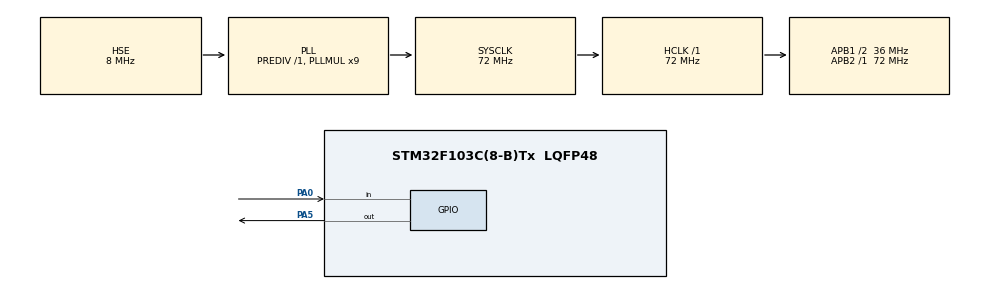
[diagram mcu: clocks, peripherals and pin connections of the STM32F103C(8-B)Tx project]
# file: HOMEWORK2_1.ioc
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Mcu.Family=STM32F1
Mcu.Name=STM32F103C(8-B)Tx
Mcu.Package=LQFP48
NVIC.PriorityGroup=NVIC_PRIORITYGROUP_4
NVIC.TIM3_IRQn=true\:0\:0\:false\:false\:true\:true\:true\:true
PA0-WKUP.GPIO_PuPd=GPIO_PULLUP
PA0-WKUP.Signal=GPIO_Input
PA13.Mode=Serial_Wire
PA13.Signal=SYS_JTMS-SWDIO
PA14.Mode=Serial_Wire
PA14.Signal=SYS_JTCK-SWCLK
PA5.Signal=GPIO_Output
PD0-OSC_IN.Mode=HSE-External-Oscillator
PD0-OSC_IN.Signal=RCC_OSC_IN
PD1-OSC_OUT.Mode=HSE-External-Oscillator
PD1-OSC_OUT.Signal=RCC_OSC_OUT
ProjectManager.HeapSize=0x200
ProjectManager.StackSize=0x400
ProjectManager.TargetToolchain=MDK-ARM V5.32
RCC.AHBFreq_Value=72000000
RCC.APB1CLKDivider=RCC_HCLK_DIV2
RCC.APB1Freq_Value=36000000
RCC.APB1TimFreq_Value=72000000
RCC.APB2Freq_Value=72000000
RCC.APB2TimFreq_Value=72000000
RCC.HCLKFreq_Value=72000000
RCC.PLLMUL=RCC_PLL_MUL9
RCC.PLLSourceVirtual=RCC_PLLSOURCE_HSE
RCC.SYSCLKFreq_VALUE=72000000
RCC.SYSCLKSource=RCC_SYSCLKSOURCE_PLLCLK
RCC.USBFreq_Value=72000000
TIM3.Period=999
TIM3.Prescaler=72
VP_TIM3_VS_ClockSourceINT.Mode=Internal
board=custom

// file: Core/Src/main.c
/* USER CODE BEGIN Header */
/**
  ******************************************************************************
  * @file           : main.c
  * @brief          : Main program body
  ******************************************************************************
  * @attention
  *
  * Copyright (c) 2026 STMicroelectronics.
  * All rights reserved.
  *
  * This software is licensed under terms that can be found in the LICENSE file
  * in the root directory of this software component.
  * If no LICENSE file comes with this software, it is provided AS-IS.
  *
  ******************************************************************************
  */
/* USER CODE END Header */
#include "main.h"

TIM_HandleTypeDef htim3;

void SystemClock_Config(void);
static void MX_GPIO_Init(void);
static void MX_TIM3_Init(void);

/* USER CODE BEGIN 0 */
volatile uint32_t lunxun1ms =0;//1ms轮询计数
volatile uint32_t led_est =0;//老灯的状态
volatile uint32_t butten_est =0;//按键的状态
volatile uint32_t butten_time =0;//按键按下的时间
volatile uint32_t led_flash_time =0;//快闪时间
/* USER CODE END 0 */

int main(void)
{

  /* MCU Configuration--------------------------------------------------------*/

  /* Reset of all peripherals, Initializes the Flash interface and the Systick. */
  HAL_Init();

  /* Configure the system clock */
  SystemClock_Config();

  /* Initialize all configured peripherals */
  MX_GPIO_Init();
  MX_TIM3_Init();
  /* USER CODE BEGIN 2 */
HAL_TIM_Base_Start_IT(&htim3);//启动定时器3中断
  /* USER CODE END 2 */

  /* Infinite loop */
  while (1)
  {

    /* USER CODE BEGIN 3 */
    if (butten_est == 0)//按键不动
    {
      if (HAL_GPIO_ReadPin(GPIOA, GPIO_PIN_0) == GPIO_PIN_RESET)//按键按下
      {
        butten_est = 1;//按键状态为按下
        butten_time = lunxun1ms;//记录按键按下的时间
      }
    }
    else if (butten_est == 1)//按键按下
    {
      if (HAL_GPIO_ReadPin(GPIOA, GPIO_PIN_0) == GPIO_PIN_SET)//按键松开
      {

        butten_time = lunxun1ms - butten_time;//计算按键按下的时间
        if (butten_time >= 20)
        {
          if(butten_time < 1000)//按键按下时间小于1秒
          {
            if(led_est ==1)
            led_est =0;//老灯熄灭
            else
            led_est =1;//老灯一直亮
          }
          else if(butten_time >= 1000)//按键按下时间大于等于1秒
          {
            if(led_est ==2)
            {
              led_est =0;//老灯熄灭
            }
            else
            {
              led_est =2;//老灯快闪
              led_flash_time = lunxun1ms;//记录快闪开始的时间
            }
          }
        }
        butten_est = 0;//按钮归零
      }
    }
    //灯光明天做上面的代码别改(；′⌒`)累死了
    if (led_est == 0)//老灯熄灭
    {
      HAL_GPIO_WritePin(GPIOA, GPIO_PIN_5, GPIO_PIN_RESET);//PA5引脚输出低电平
    }
    else if (led_est == 1)//老灯一直亮
    {
      HAL_GPIO_WritePin(GPIOA, GPIO_PIN_5, GPIO_PIN_SET);//PA5引脚输出高电平
    }
    else if (led_est == 2)//老灯快闪
    {
      if (lunxun1ms - led_flash_time >= 100)//快闪时间为100ms
      {
        HAL_GPIO_TogglePin(GPIOA, GPIO_PIN_5);//将大灯逆转吧hhhhhh
        led_flash_time = lunxun1ms;//记录快闪开始的时间
      }
    }

  }
  /* USER CODE END 3 */
}

void SystemClock_Config(void)
{
  RCC_OscInitTypeDef RCC_OscInitStruct = {0};
  RCC_ClkInitTypeDef RCC_ClkInitStruct = {0};

  /** Initializes the RCC Oscillators according to the specified parameters
  * in the RCC_OscInitTypeDef structure.
  */
  RCC_OscInitStruct.OscillatorType = RCC_OSCILLATORTYPE_HSE;
  RCC_OscInitStruct.HSEState = RCC_HSE_ON;
  RCC_OscInitStruct.HSEPredivValue = RCC_HSE_PREDIV_DIV1;
  RCC_OscInitStruct.HSIState = RCC_HSI_ON;
  RCC_OscInitStruct.PLL.PLLState = RCC_PLL_ON;
  RCC_OscInitStruct.PLL.PLLSource = RCC_PLLSOURCE_HSE;
  RCC_OscInitStruct.PLL.PLLMUL = RCC_PLL_MUL9;
  if (HAL_RCC_OscConfig(&RCC_OscInitStruct) != HAL_OK)
  {
    Error_Handler();
  }

  /** Initializes the CPU, AHB and APB buses clocks
  */
  RCC_ClkInitStruct.ClockType = RCC_CLOCKTYPE_HCLK|RCC_CLOCKTYPE_SYSCLK
                              |RCC_CLOCKTYPE_PCLK1|RCC_CLOCKTYPE_PCLK2;
  RCC_ClkInitStruct.SYSCLKSource = RCC_SYSCLKSOURCE_PLLCLK;
  RCC_ClkInitStruct.AHBCLKDivider = RCC_SYSCLK_DIV1;
  RCC_ClkInitStruct.APB1CLKDivider = RCC_HCLK_DIV2;
  RCC_ClkInitStruct.APB2CLKDivider = RCC_HCLK_DIV1;

  if (HAL_RCC_ClockConfig(&RCC_ClkInitStruct, FLASH_LATENCY_2) != HAL_OK)
  {
    Error_Handler();
  }
}

static void MX_TIM3_Init(void)
{

  TIM_ClockConfigTypeDef sClockSourceConfig = {0};
  TIM_MasterConfigTypeDef sMasterConfig = {0};

  htim3.Instance = TIM3;
  htim3.Init.Prescaler = 72;
  htim3.Init.CounterMode = TIM_COUNTERMODE_UP;
  htim3.Init.Period = 999;
  htim3.Init.ClockDivision = TIM_CLOCKDIVISION_DIV1;
  htim3.Init.AutoReloadPreload = TIM_AUTORELOAD_PRELOAD_DISABLE;
  if (HAL_TIM_Base_Init(&htim3) != HAL_OK)
  {
    Error_Handler();
  }
  sClockSourceConfig.ClockSource = TIM_CLOCKSOURCE_INTERNAL;
  if (HAL_TIM_ConfigClockSource(&htim3, &sClockSourceConfig) != HAL_OK)
  {
    Error_Handler();
  }
  sMasterConfig.MasterOutputTrigger = TIM_TRGO_RESET;
  sMasterConfig.MasterSlaveMode = TIM_MASTERSLAVEMODE_DISABLE;
  if (HAL_TIMEx_MasterConfigSynchronization(&htim3, &sMasterConfig) != HAL_OK)
  {
    Error_Handler();
  }

}

static void MX_GPIO_Init(void)
{
  GPIO_InitTypeDef GPIO_InitStruct = {0};

  /* GPIO Ports Clock Enable */
  __HAL_RCC_GPIOD_CLK_ENABLE();
  __HAL_RCC_GPIOA_CLK_ENABLE();

  /*Configure GPIO pin Output Level */
  HAL_GPIO_WritePin(GPIOA, GPIO_PIN_5, GPIO_PIN_RESET);

  /*Configure GPIO pin : PA0 */
  GPIO_InitStruct.Pin = GPIO_PIN_0;
  GPIO_InitStruct.Mode = GPIO_MODE_INPUT;
  GPIO_InitStruct.Pull = GPIO_PULLUP;
  HAL_GPIO_Init(GPIOA, &GPIO_InitStruct);

  /*Configure GPIO pin : PA5 */
  GPIO_InitStruct.Pin = GPIO_PIN_5;
  GPIO_InitStruct.Mode = GPIO_MODE_OUTPUT_PP;
  GPIO_InitStruct.Pull = GPIO_NOPULL;
  GPIO_InitStruct.Speed = GPIO_SPEED_FREQ_LOW;
  HAL_GPIO_Init(GPIOA, &GPIO_InitStruct);

}

/* USER CODE BEGIN 4 */
void HAL_TIM_PeriodElapsedCallback(TIM_HandleTypeDef *htim)
{
  if(htim->Instance == TIM3)//判断是否为定时器3触发的中断
  {
    lunxun1ms++;//1ms轮询计数
  }
}
/* USER CODE END 4 */

void Error_Handler(void)
{
  __disable_irq();
  while (1)
  {
  }
}
